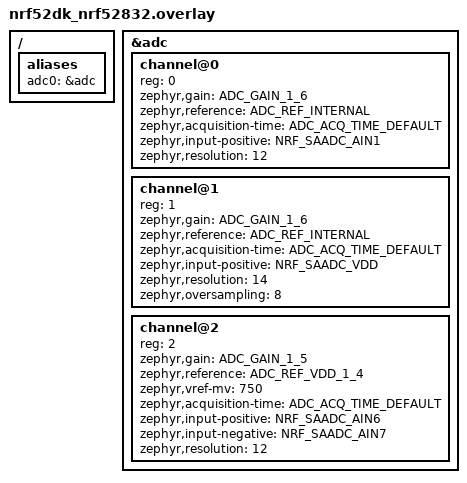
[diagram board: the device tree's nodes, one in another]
/*
 * SPDX-License-Identifier: Apache-2.0
 *
 * Copyright (c) 2026 Smile
 */

/ {
	aliases {
		adc0 = &adc;
	};
};

&adc {
	#address-cells = <1>;
	#size-cells = <0>;

	channel@0 {
		reg = <0>;
		zephyr,gain = "ADC_GAIN_1_6";
		zephyr,reference = "ADC_REF_INTERNAL";
		zephyr,acquisition-time = <ADC_ACQ_TIME_DEFAULT>;
		zephyr,input-positive = <NRF_SAADC_AIN1>; /* P0.03 */
		zephyr,resolution = <12>;
	};

	channel@1 {
		reg = <1>;
		zephyr,gain = "ADC_GAIN_1_6";
		zephyr,reference = "ADC_REF_INTERNAL";
		zephyr,acquisition-time = <ADC_ACQ_TIME_DEFAULT>;
		zephyr,input-positive = <NRF_SAADC_VDD>;
		zephyr,resolution = <14>;
		zephyr,oversampling = <8>;
	};

	channel@2 {
		reg = <2>;
		zephyr,gain = "ADC_GAIN_1_5";
		zephyr,reference = "ADC_REF_VDD_1_4";
		zephyr,vref-mv = <750>;
		zephyr,acquisition-time = <ADC_ACQ_TIME_DEFAULT>;
		zephyr,input-positive = <NRF_SAADC_AIN6>; /* P0.30 */
		zephyr,input-negative = <NRF_SAADC_AIN7>; /* P0.31 */
		zephyr,resolution = <12>;
	};
};
